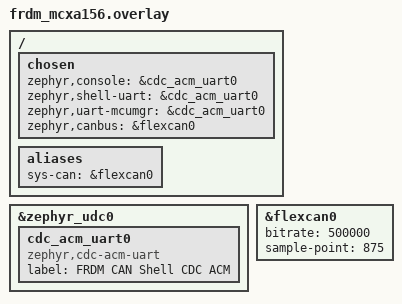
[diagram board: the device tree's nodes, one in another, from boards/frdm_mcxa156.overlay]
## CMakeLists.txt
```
# SPDX-License-Identifier: Apache-2.0

cmake_minimum_required(VERSION 3.20.0)

find_package(Zephyr REQUIRED HINTS $ENV{ZEPHYR_BASE})
project(frdm_can_shell_monitor_cdc)

target_sources(app PRIVATE src/main.c)
```

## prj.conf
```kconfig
# FRDM CAN shell monitor over USB CDC ACM.
#
# The useful CAN behavior comes from Zephyr's CAN shell. The app only hosts
# the shell and lets the browser or terminal send documented shell commands.

CONFIG_USB_DEVICE_STACK_NEXT=y
CONFIG_CDC_ACM_SERIAL_INITIALIZE_AT_BOOT=y
CONFIG_CDC_ACM_SERIAL_PRODUCT_STRING="FRDM CAN Shell Monitor"

CONFIG_SERIAL=y
CONFIG_CONSOLE=y
CONFIG_UART_CONSOLE=y
CONFIG_UART_LINE_CTRL=y
CONFIG_STDOUT_CONSOLE=y

CONFIG_LOG=y
CONFIG_LOG_CMDS=y
CONFIG_USBD_CDC_ACM_LOG_LEVEL_OFF=y
CONFIG_USBD_LOG_LEVEL_OFF=y
CONFIG_UDC_DRIVER_LOG_LEVEL_OFF=y

CONFIG_SHELL=y
CONFIG_SHELL_HELP=y
CONFIG_SHELL_HISTORY=y
CONFIG_SHELL_DEVICE_HELPERS=y
CONFIG_SHELL_BACKEND_SERIAL_CHECK_DTR=y
CONFIG_SHELL_BACKEND_SERIAL_TX_RING_BUFFER_SIZE=2048
CONFIG_SHELL_BACKEND_SERIAL_RX_RING_BUFFER_SIZE=256
CONFIG_SHELL_PROMPT_UART="frdm-can:~$ "

CONFIG_DEVICE_SHELL=y
CONFIG_DEVICE_DT_METADATA=y

CONFIG_REBOOT=y
CONFIG_KERNEL_SHELL=y
CONFIG_THREAD_MONITOR=y

CONFIG_CAN=y
CONFIG_CAN_DEFAULT_BITRATE=500000
CONFIG_CAN_SHELL=y
CONFIG_CAN_SHELL_SCRIPTING_FRIENDLY=y
CONFIG_CAN_SHELL_RX_QUEUE_SIZE=64
CONFIG_CAN_RX_TIMESTAMP=y
CONFIG_CAN_ACCEPT_RTR=y

CONFIG_STATS=y
CONFIG_STATS_NAMES=y
CONFIG_STATS_SHELL=y
CONFIG_CAN_STATS=y
```

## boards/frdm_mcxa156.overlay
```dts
/*
 * FRDM-MCXA156 USB CDC shell routing plus CAN shell-friendly naming.
 */

/ {
	chosen {
		zephyr,console = &cdc_acm_uart0;
		zephyr,shell-uart = &cdc_acm_uart0;
		zephyr,uart-mcumgr = &cdc_acm_uart0;
		zephyr,canbus = &flexcan0;
	};

	aliases {
		sys-can = &flexcan0;
	};
};

&zephyr_udc0 {
	cdc_acm_uart0: cdc_acm_uart0 {
		compatible = "zephyr,cdc-acm-uart";
		label = "FRDM CAN Shell CDC ACM";
	};
};

can0: &flexcan0 {
	status = "okay";
	bitrate = <500000>;
	sample-point = <875>;
};
```

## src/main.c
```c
/*
 * SPDX-License-Identifier: Apache-2.0
 *
 * FRDM CAN shell monitor over USB CDC ACM.
 *
 * The application code intentionally stays minimal. CAN inspection,
 * filtering, sending, and receiving are exposed by CONFIG_CAN_SHELL.
 */

#include <zephyr/kernel.h>
#include <zephyr/sys/printk.h>

int main(void)
{
	printk("FRDM CAN shell monitor ready. Use `help`, `device list`, and `can`.\n");

	while (true) {
		k_sleep(K_SECONDS(1));
	}

	return 0;
}
```
